# iospear310 register map
Registers are 32-bit, access not given, no defined reset value unless marked. A register's access mark holds for its fields unless they carry their own. Addresses are absolute; registers are grouped by the start of their names; [hi:lo] are bit positions; 'fields as' and 'values as' point back to an identical list.

## Txoctetcount
0xE0800114 Txoctetcount_gb
0xE0800164 Txoctetcount_g

## Txbroadcastframes
0xE080011C Txbroadcastframes_g
0xE0800144 Txbroadcastframes_gb

## Txmulticastframes
0xE0800120 Txmulticastframes_g
0xE0800140 Txmulticastframes_gb

## Rxoctetcount
0xE0800184 Rxoctetcount_gb
0xE0800188 Rxoctetcount_g

## IrDA
0xD1000010 IrDA_CON
  [0] RUN
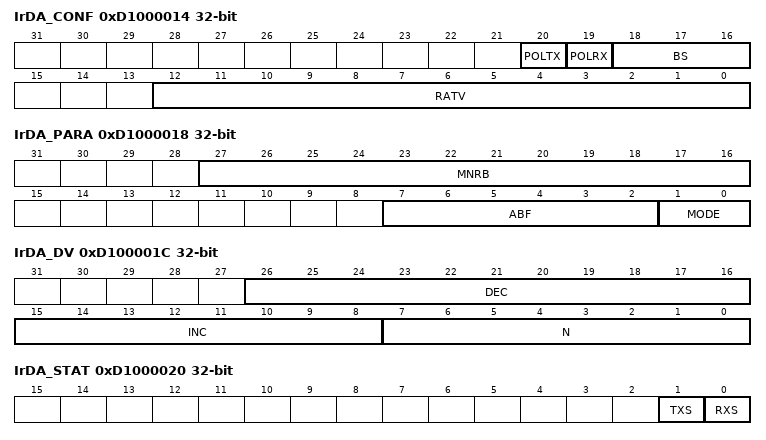
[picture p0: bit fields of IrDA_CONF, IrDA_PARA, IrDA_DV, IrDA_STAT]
0xD1000014 IrDA_CONF
  [20] POLTX, [19] POLRX, [18:16] BS, [12:0] RATV
0xD1000018 IrDA_PARA
  [27:16] MNRB, [7:2] ABF, [1:0] MODE
0xD100001C IrDA_DV
  [26:16] DEC, [15:8] INC, [7:0] N
0xD1000020 IrDA_STAT
  [1] TXS, [0] RXS
0xD1000024 IrDA_TFS
  [11:0] TFS
0xD1000028 IrDA_RFS
  [11:0] RFS
0xD100002C IrDA_TXB
0xD1000030 IrDA_RXB
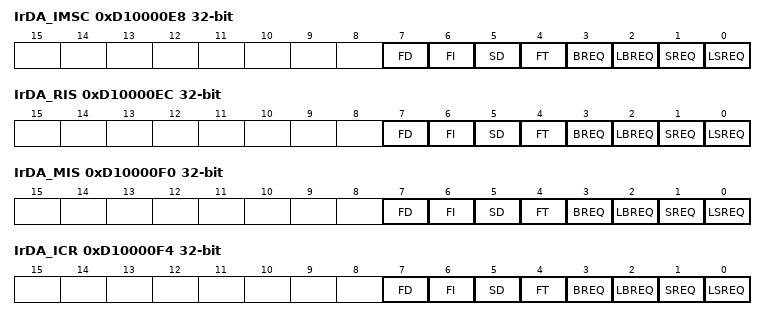
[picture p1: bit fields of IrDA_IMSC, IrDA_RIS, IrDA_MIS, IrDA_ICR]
0xD10000E8 IrDA_IMSC
  [7] FD, [6] FI, [5] SD, [4] FT, [3] BREQ, [2] LBREQ, [1] SREQ, [0] LSREQ
0xD10000EC IrDA_RIS
  fields as IrDA_IMSC
0xD10000F0 IrDA_MIS
  fields as IrDA_IMSC
0xD10000F4 IrDA_ICR
  fields as IrDA_IMSC
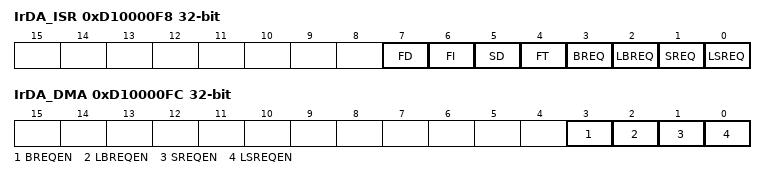
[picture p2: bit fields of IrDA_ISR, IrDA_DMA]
0xD10000F8 IrDA_ISR
  fields as IrDA_IMSC
0xD10000FC IrDA_DMA
  [3] BREQEN, [2] LBREQEN, [1] SREQEN, [0] LSREQEN

## IC
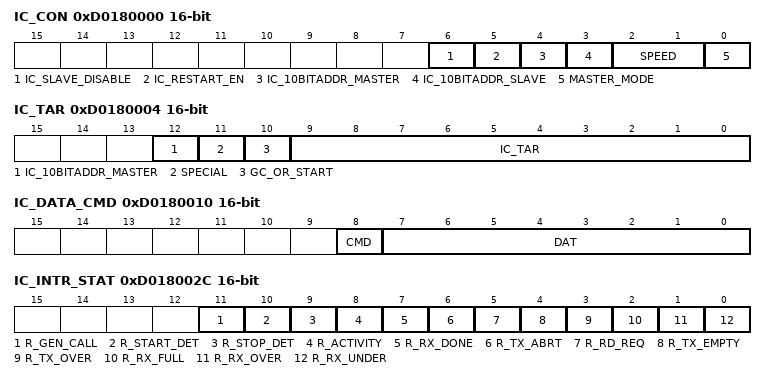
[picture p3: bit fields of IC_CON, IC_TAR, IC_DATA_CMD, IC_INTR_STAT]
0xD0180000 IC_CON 16-bit
  [6] IC_SLAVE_DISABLE, [5] IC_RESTART_EN, [4] IC_10BITADDR_MASTER, [3] IC_10BITADDR_SLAVE, [2:1] SPEED, [0] MASTER_MODE
0xD0180004 IC_TAR 16-bit
  [12] IC_10BITADDR_MASTER, [11] SPECIAL, [10] GC_OR_START, [9:0] IC_TAR
0xD0180008 IC_SAR 16-bit
  [9:0] IC_SAR
0xD018000C IC_HS_MADDR 16-bit
  [2:0] IC_HS_MAR
0xD0180010 IC_DATA_CMD 16-bit
  [8] CMD, [7:0] DAT
0xD0180014 IC_SS_SCL_HCNT 16-bit
0xD0180018 IC_SS_SCL_LCNT 16-bit
0xD018001C IC_FS_SCL_HCNT 16-bit
0xD0180020 IC_FS_SCL_LCNT 16-bit
0xD0180024 IC_HS_SCL_HCNT 16-bit
0xD0180028 IC_HS_SCL_LCNT 16-bit
0xD018002C IC_INTR_STAT 16-bit
  [11] R_GEN_CALL, [10] R_START_DET, [9] R_STOP_DET, [8] R_ACTIVITY, [7] R_RX_DONE, [6] R_TX_ABRT, [5] R_RD_REQ, [4] R_TX_EMPTY, [3] R_TX_OVER, [2] R_RX_FULL, [1] R_RX_OVER, [0] R_RX_UNDER
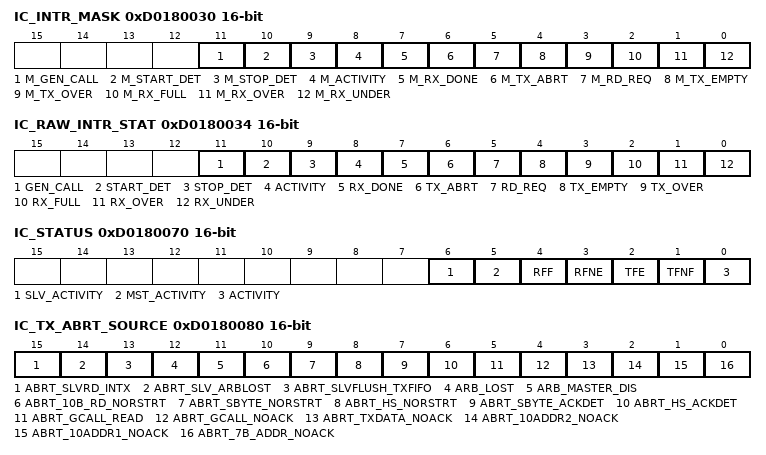
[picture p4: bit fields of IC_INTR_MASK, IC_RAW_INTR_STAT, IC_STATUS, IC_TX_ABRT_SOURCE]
0xD0180030 IC_INTR_MASK 16-bit
  [11] M_GEN_CALL, [10] M_START_DET, [9] M_STOP_DET, [8] M_ACTIVITY, [7] M_RX_DONE, [6] M_TX_ABRT, [5] M_RD_REQ, [4] M_TX_EMPTY, [3] M_TX_OVER, [2] M_RX_FULL, [1] M_RX_OVER, [0] M_RX_UNDER
0xD0180034 IC_RAW_INTR_STAT 16-bit
  [11] GEN_CALL, [10] START_DET, [9] STOP_DET, [8] ACTIVITY, [7] RX_DONE, [6] TX_ABRT, [5] RD_REQ, [4] TX_EMPTY, [3] TX_OVER, [2] RX_FULL, [1] RX_OVER, [0] RX_UNDER
0xD0180038 IC_RX_TL 16-bit
  [7:0] RX_TL
0xD018003C IC_TX_TL 16-bit
  [7:0] TX_TL
0xD0180040 IC_CLR_INTR 16-bit
  [0] CLR_INTR
0xD0180044 IC_CLR_RX_UNDER 16-bit
0xD0180048 IC_CLR_RX_OVER 16-bit
0xD018004C IC_CLR_TX_OVER 16-bit
0xD0180050 IC_CLR_RD_REQ 16-bit
0xD0180054 IC_CLR_TX_ABRT 16-bit
0xD0180058 IC_CLR_RX_DONE 16-bit
0xD018005C IC_CLR_ACTIVITY 16-bit
0xD0180060 IC_CLR_STOP_DET 16-bit
0xD0180064 IC_CLR_START_DET 16-bit
0xD0180068 IC_CLR_GEN_CALL 16-bit
0xD018006C IC_ENABLE 16-bit
  [0] ENABLE
0xD0180070 IC_STATUS 16-bit
  [6] SLV_ACTIVITY, [5] MST_ACTIVITY, [4] RFF, [3] RFNE, [2] TFE, [1] TFNF, [0] ACTIVITY
0xD0180074 IC_TXFLR 16-bit
  [3:0] TXFLR
0xD0180078 IC_RXFLR 16-bit
  [3:0] RXFLR
0xD0180080 IC_TX_ABRT_SOURCE 16-bit
  [15] ABRT_SLVRD_INTX, [14] ABRT_SLV_ARBLOST, [13] ABRT_SLVFLUSH_TXFIFO, [12] ARB_LOST, [11] ARB_MASTER_DIS, [10] ABRT_10B_RD_NORSTRT, [9] ABRT_SBYTE_NORSTRT, [8] ABRT_HS_NORSTRT, [7] ABRT_SBYTE_ACKDET, [6] ABRT_HS_ACKDET, [5] ABRT_GCALL_READ, [4] ABRT_GCALL_NOACK, [3] ABRT_TXDATA_NOACK, [2] ABRT_10ADDR2_NOACK, [1] ABRT_10ADDR1_NOACK, [0] ABRT_7B_ADDR_NOACK
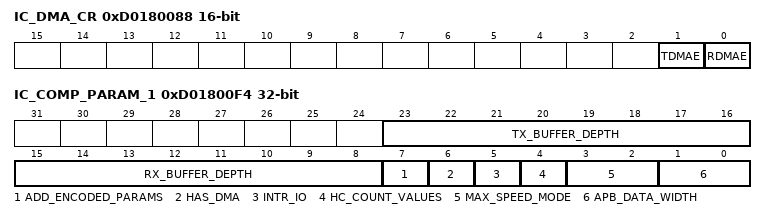
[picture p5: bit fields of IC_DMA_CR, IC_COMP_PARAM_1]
0xD0180088 IC_DMA_CR 16-bit
  [1] TDMAE, [0] RDMAE
0xD018008C IC_DMA_TDLR 16-bit
  [2:0] DMATDL
0xD0180090 IC_DMA_RDLR 16-bit
  [2:0] DMARDL
0xD01800F4 IC_COMP_PARAM_1
  [23:16] TX_BUFFER_DEPTH, [15:8] RX_BUFFER_DEPTH, [7] ADD_ENCODED_PARAMS, [6] HAS_DMA, [5] INTR_IO, [4] HC_COUNT_VALUES, [3:2] MAX_SPEED_MODE, [1:0] APB_DATA_WIDTH
0xD01800F8 IC_COMP_VERSION
0xD01800FC IC_COMP_TYPE
